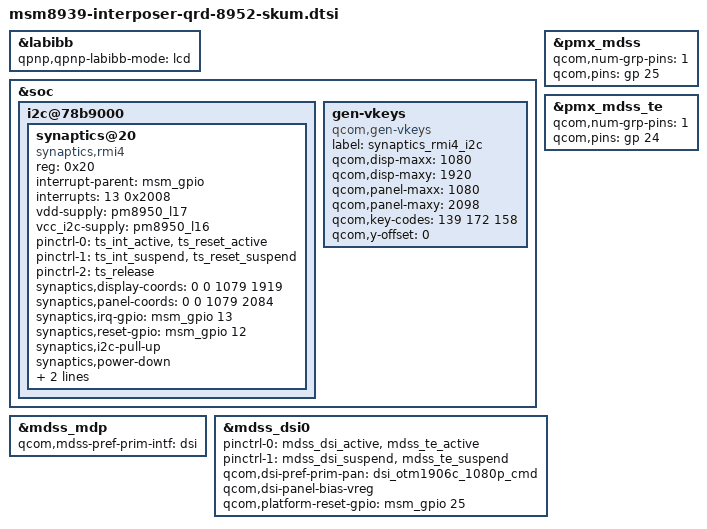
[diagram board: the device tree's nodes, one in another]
/*
 * Copyright (c) 2015, The Linux Foundation. All rights reserved.
 *
 * This program is free software; you can redistribute it and/or modify
 * it under the terms of the GNU General Public License version 2 and
 * only version 2 as published by the Free Software Foundation.
 *
 * This program is distributed in the hope that it will be useful,
 * but WITHOUT ANY WARRANTY; without even the implied warranty of
 * MERCHANTABILITY or FITNESS FOR A PARTICULAR PURPOSE.  See the
 * GNU General Public License for more details.
 */

#include "msm8939-interposer-qrd.dtsi"
#include "dsi-panel-otm1906c-1080p-cmd.dtsi"

&labibb {
	status = "ok";
	qpnp,qpnp-labibb-mode = "lcd";
};

&soc {
	i2c@78b9000 { /* BLSP1 QUP5 */
		synaptics@20 {
			compatible = "synaptics,rmi4";
			reg = <0x20>;
			interrupt-parent = <&msm_gpio>;
			interrupts = <13 0x2008>;
			vdd-supply = <&pm8950_l17>;
			vcc_i2c-supply = <&pm8950_l16>;
			/* pins used by touchscreen */
			pinctrl-names = "pmx_ts_active","pmx_ts_suspend","pmx_ts_suspend";
			pinctrl-0 = <&ts_int_active &ts_reset_active>;
			pinctrl-1 = <&ts_int_suspend &ts_reset_suspend>;
			pinctrl-2 = <&ts_release>;
			synaptics,display-coords = <0 0 1079 1919>;
			synaptics,panel-coords = <0 0 1079 2084>;
			synaptics,irq-gpio = <&msm_gpio 13 0x2008>;
			synaptics,reset-gpio = <&msm_gpio 12 0x0>;
			synaptics,i2c-pull-up;
			synaptics,power-down;
			synaptics,disable-gpios;
			synaptics,button-map = <139 172 158>;
		};
	};

	gen-vkeys {
		compatible = "qcom,gen-vkeys";
		label = "synaptics_rmi4_i2c";
		qcom,disp-maxx = <1080>;
		qcom,disp-maxy = <1920>;
		qcom,panel-maxx = <1080>;
		qcom,panel-maxy = <2098>;
		qcom,key-codes = <139 172 158>;
		qcom,y-offset = <0>;
	};
};

&mdss_mdp {
	qcom,mdss-pref-prim-intf = "dsi";
};

&pmx_mdss {
	qcom,num-grp-pins = <1>;
	qcom,pins = <&gp 25>;
};

&pmx_mdss_te {
	qcom,num-grp-pins = <1>;
	qcom,pins = <&gp 24>;
};

&mdss_dsi0 {
	pinctrl-names = "mdss_default", "mdss_sleep";
	pinctrl-0 = <&mdss_dsi_active &mdss_te_active>;
	pinctrl-1 = <&mdss_dsi_suspend &mdss_te_suspend>;
	qcom,dsi-pref-prim-pan = <&dsi_otm1906c_1080p_cmd>;
	qcom,dsi-panel-bias-vreg;

	qcom,platform-reset-gpio = <&msm_gpio 25 0>;
};
